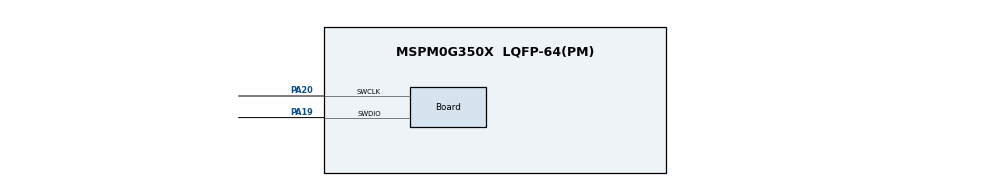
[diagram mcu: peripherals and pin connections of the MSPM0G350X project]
/**
 * @cliArgs --device "MSPM0G350X" --package "LQFP-64(PM)" --part "Default" --product "mspm0_sdk@2.00.01.00"
 * @versions {"tool":"1.20.0+3587"}
 */

/**
 * Import the modules used in this configuration.
 */
const Board         = scripting.addModule("/ti/driverlib/Board");
const COMP          = scripting.addModule("/ti/driverlib/COMP", {}, false);
const COMP1         = COMP.addInstance();
const OPA           = scripting.addModule("/ti/driverlib/OPA", {}, false);
const OPA1          = OPA.addInstance();
const SYSCTL        = scripting.addModule("/ti/driverlib/SYSCTL");
const VREF          = scripting.addModule("/ti/driverlib/VREF");
const ProjectConfig = scripting.addModule("/ti/project_config/ProjectConfig");

/**
 * Write custom configuration values to the imported modules.
 */
Board.InitPriority8               = "/ti/driverlib/VREF";
Board.peripheral.$assign          = "DEBUGSS";
Board.peripheral.swclkPin.$assign = "PA20";
Board.peripheral.swdioPin.$assign = "PA19";

COMP1.$name              = "COMP_0";
COMP1.hysteresis         = "DL_COMP_HYSTERESIS_20";
COMP1.vSource            = "DL_COMP_REF_SOURCE_VDDA_DAC";
COMP1.terminalSelect     = "DL_COMP_REF_TERMINAL_SELECT_NEG";
COMP1.controlSelect      = "DL_COMP_DAC_CONTROL_SW";
COMP1.setDACCode0        = 0x4D;
COMP1.peripheral.$assign = "COMP0";

OPA1.$name              = "OPA_0";
OPA1.cfg0OutputPin      = "ENABLED";
OPA1.cfg0PSELChannel    = "DAC8_OUT";
OPA1.cfg0NSELChannel    = "RTOP";
OPA1.advBW              = "HIGH";
OPA1.OutPinConfig.$name = "ti_driverlib_gpio_GPIOPinGeneric0";

SYSCTL.clockTreeEn = true;

VREF.checkVREFReady         = true;
VREF.basicIntVolt           = "DL_VREF_BUFCONFIG_OUTPUT_2_5V";
VREF.vrefPosPinConfig.$name = "ti_driverlib_gpio_GPIOPinGeneric1";

ProjectConfig.deviceSpin = "MSPM0G3507";

/**
 * Pinmux solution for unlocked pins/peripherals. This ensures that minor changes to the automatic solver in a future
 * version of the tool will not impact the pinmux you originally saw.  These lines can be completely deleted in order to
 * re-solve from scratch.
 */
OPA1.peripheral.$suggestSolution            = "OPA0";
OPA1.peripheral.OutPin.$suggestSolution     = "PA22";
VREF.peripheral.$suggestSolution            = "VREF";
VREF.peripheral.vrefPosPin.$suggestSolution = "PA23";
